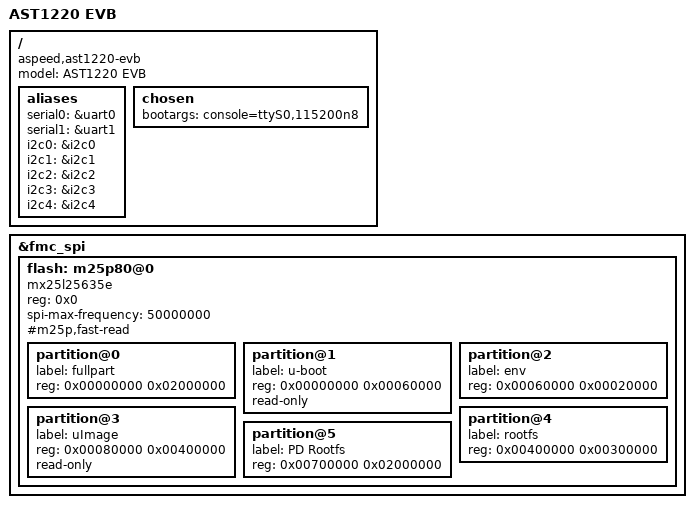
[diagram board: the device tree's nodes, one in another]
/dts-v1/;

#include "ast1220.dtsi"

/ {
	model = "AST1220 EVB";
	compatible = "aspeed,ast1220-evb", "aspeed,ast1220";

	aliases {
		serial0 = &uart0;
		serial1 = &uart1;	
		i2c0 = &i2c0;
		i2c1 = &i2c1;
		i2c2 = &i2c2;
		i2c3 = &i2c3;
		i2c4 = &i2c4;
	};


	chosen {
		bootargs = "console=ttyS0,115200n8";
	};

};

&fmc_spi {
	status = "okay";
	flash: m25p80@0 {
	compatible = "mx25l25635e", "m25p80", "jedec,spi-nor";
	reg = <0x0>;
	#address-cells = <0x1>;
	#size-cells = <0x1>;
	spi-max-frequency = <50000000>;
	#m25p,fast-read;
		partition@0 {
			label = "fullpart";
			reg = <0x00000000 0x02000000>;	
		};
		partition@1 {
			label = "u-boot";
			reg = <0x00000000 0x00060000>;
			read-only;
		};
		partition@2 {
			label = "env";
			reg = <0x00060000 0x00020000>;
		};
		partition@3 {
			label = "uImage";
			reg = <0x00080000 0x00400000>;
			read-only;
		};
		partition@4 {
			label = "rootfs";
			reg = <0x00400000 0x00300000>;
		};
		partition@5 {
			label = "PD Rootfs";
			reg = <0x00700000 0x02000000>;
		};
	};
};
